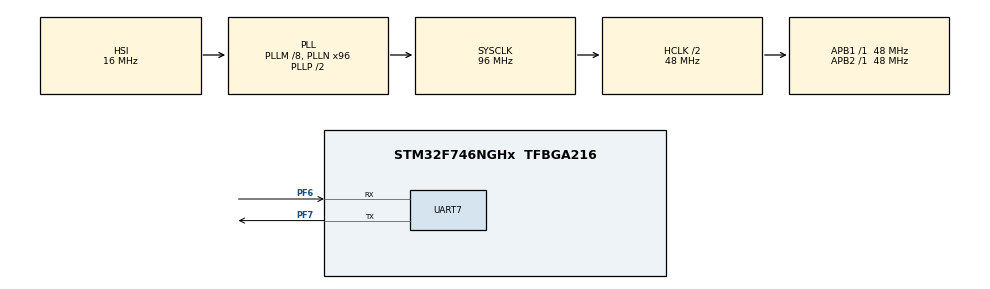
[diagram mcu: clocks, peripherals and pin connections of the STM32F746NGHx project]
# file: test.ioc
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Dma.Request0=UART7_RX
Dma.Request1=UART7_TX
Dma.UART7_RX.0.Direction=DMA_PERIPH_TO_MEMORY
Dma.UART7_RX.0.FIFOMode=DMA_FIFOMODE_DISABLE
Dma.UART7_RX.0.Instance=DMA1_Stream3
Dma.UART7_RX.0.MemDataAlignment=DMA_MDATAALIGN_BYTE
Dma.UART7_RX.0.MemInc=DMA_MINC_ENABLE
Dma.UART7_RX.0.Mode=DMA_NORMAL
Dma.UART7_RX.0.PeriphDataAlignment=DMA_PDATAALIGN_BYTE
Dma.UART7_RX.0.PeriphInc=DMA_PINC_DISABLE
Dma.UART7_RX.0.Priority=DMA_PRIORITY_LOW
Dma.UART7_TX.1.Direction=DMA_MEMORY_TO_PERIPH
Dma.UART7_TX.1.FIFOMode=DMA_FIFOMODE_DISABLE
Dma.UART7_TX.1.Instance=DMA1_Stream1
Dma.UART7_TX.1.MemDataAlignment=DMA_MDATAALIGN_BYTE
Dma.UART7_TX.1.MemInc=DMA_MINC_ENABLE
Dma.UART7_TX.1.Mode=DMA_NORMAL
Dma.UART7_TX.1.PeriphDataAlignment=DMA_PDATAALIGN_BYTE
Dma.UART7_TX.1.PeriphInc=DMA_PINC_DISABLE
Dma.UART7_TX.1.Priority=DMA_PRIORITY_LOW
Mcu.Family=STM32F7
Mcu.Name=STM32F746NGHx
Mcu.Package=TFBGA216
NVIC.DMA1_Stream1_IRQn=true\:0\:0\:false\:false\:true\:false
NVIC.DMA1_Stream3_IRQn=true\:0\:0\:false\:false\:true\:false
NVIC.PriorityGroup=NVIC_PRIORITYGROUP_4
NVIC.UART7_IRQn=true\:0\:0\:false\:false\:true\:true
PF6.Mode=Asynchronous
PF6.Signal=UART7_RX
PF7.Mode=Asynchronous
PF7.Signal=UART7_TX
ProjectManager.HeapSize=0x200
ProjectManager.StackSize=0x400
ProjectManager.TargetToolchain=MDK-ARM V5
RCC.AHBCLKDivider=RCC_SYSCLK_DIV2
RCC.AHBFreq_Value=48000000
RCC.APB1Freq_Value=48000000
RCC.APB1TimFreq_Value=48000000
RCC.APB2Freq_Value=48000000
RCC.APB2TimFreq_Value=48000000
RCC.CortexFreq_Value=48000000
RCC.HCLKFreq_Value=48000000
RCC.HSE_VALUE=25000000
RCC.HSI_VALUE=16000000
RCC.LSE_VALUE=32768
RCC.PLLM=8
RCC.PLLN=96
RCC.SYSCLKFreq_VALUE=96000000
RCC.SYSCLKSource=RCC_SYSCLKSOURCE_PLLCLK
RCC.USBFreq_Value=96000000
RCC.VCOOutputFreq_Value=192000000
board=custom

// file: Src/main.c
/* USER CODE BEGIN Header */
/**
  ******************************************************************************
  * @file           : main.c
  * @brief          : Main program body
  ******************************************************************************
  ** This notice applies to any and all portions of this file
  * that are not between comment pairs USER CODE BEGIN and
  * USER CODE END. Other portions of this file, whether
  * inserted by the user or by software development tools
  * are owned by their respective copyright owners.
  *
  * COPYRIGHT(c) 2019 STMicroelectronics
  *
  * Redistribution and use in source and binary forms, with or without modification,
  * are permitted provided that the following conditions are met:
  *   1. Redistributions of source code must retain the above copyright notice,
  *      this list of conditions and the following disclaimer.
  *   2. Redistributions in binary form must reproduce the above copyright notice,
  *      this list of conditions and the following disclaimer in the documentation
  *      and/or other materials provided with the distribution.
  *   3. Neither the name of STMicroelectronics nor the names of its contributors
  *      may be used to endorse or promote products derived from this software
  *      without specific prior written permission.
  *
  * THIS SOFTWARE IS PROVIDED BY THE COPYRIGHT HOLDERS AND CONTRIBUTORS "AS IS"
  * AND ANY EXPRESS OR IMPLIED WARRANTIES, INCLUDING, BUT NOT LIMITED TO, THE
  * IMPLIED WARRANTIES OF MERCHANTABILITY AND FITNESS FOR A PARTICULAR PURPOSE ARE
  * DISCLAIMED. IN NO EVENT SHALL THE COPYRIGHT HOLDER OR CONTRIBUTORS BE LIABLE
  * FOR ANY DIRECT, INDIRECT, INCIDENTAL, SPECIAL, EXEMPLARY, OR CONSEQUENTIAL
  * DAMAGES (INCLUDING, BUT NOT LIMITED TO, PROCUREMENT OF SUBSTITUTE GOODS OR
  * SERVICES; LOSS OF USE, DATA, OR PROFITS; OR BUSINESS INTERRUPTION) HOWEVER
  * CAUSED AND ON ANY THEORY OF LIABILITY, WHETHER IN CONTRACT, STRICT LIABILITY,
  * OR TORT (INCLUDING NEGLIGENCE OR OTHERWISE) ARISING IN ANY WAY OUT OF THE USE
  * OF THIS SOFTWARE, EVEN IF ADVISED OF THE POSSIBILITY OF SUCH DAMAGE123.
  *
  ******************************************************************************
  */
/* USER CODE END Header */

#include "main.h"
#include "dma.h"
#include "usart.h"
#include "gpio.h"

/* USER CODE BEGIN Includes */
HAL_StatusTypeDef state;
/* USER CODE END Includes */

/* USER CODE BEGIN PTD */
 //this is just for testing git
/* USER CODE END PTD */

void SystemClock_Config(void);

/* USER CODE BEGIN 0 */
uint8_t transfer_buffer[]="hello world\r\n";
/* USER CODE END 0 */

int main(void)
{

  /* MCU Configuration--------------------------------------------------------*/

  /* Reset of all peripherals, Initializes the Flash interface and the Systick. */
  HAL_Init();

  /* Configure the system clock */
  SystemClock_Config();

  /* Initialize all configured peripherals */
  MX_GPIO_Init();
  MX_DMA_Init();
  MX_UART7_Init();

  /* Infinite loop */
  while (1)
  {

    /* USER CODE BEGIN 3 */
//		HAL_UART_Transmit_DMA(&huart7, transfer_buffer, sizeof(transfer_buffer)-1);
		printf(transfer_buffer);
		HAL_Delay(700);
  }
  /* USER CODE END 3 */
}

void SystemClock_Config(void)
{
  RCC_OscInitTypeDef RCC_OscInitStruct = {0};
  RCC_ClkInitTypeDef RCC_ClkInitStruct = {0};
  RCC_PeriphCLKInitTypeDef PeriphClkInitStruct = {0};

  /**Configure the main internal regulator output voltage
  */
  __HAL_RCC_PWR_CLK_ENABLE();
  __HAL_PWR_VOLTAGESCALING_CONFIG(PWR_REGULATOR_VOLTAGE_SCALE3);
  /**Initializes the CPU, AHB and APB busses clocks
  */
  RCC_OscInitStruct.OscillatorType = RCC_OSCILLATORTYPE_HSI;
  RCC_OscInitStruct.HSIState = RCC_HSI_ON;
  RCC_OscInitStruct.HSICalibrationValue = RCC_HSICALIBRATION_DEFAULT;
  RCC_OscInitStruct.PLL.PLLState = RCC_PLL_ON;
  RCC_OscInitStruct.PLL.PLLSource = RCC_PLLSOURCE_HSI;
  RCC_OscInitStruct.PLL.PLLM = 8;
  RCC_OscInitStruct.PLL.PLLN = 96;
  RCC_OscInitStruct.PLL.PLLP = RCC_PLLP_DIV2;
  RCC_OscInitStruct.PLL.PLLQ = 2;
  if (HAL_RCC_OscConfig(&RCC_OscInitStruct) != HAL_OK)
  {
    Error_Handler();
  }
  /**Activate the Over-Drive mode
  */
  if (HAL_PWREx_EnableOverDrive() != HAL_OK)
  {
    Error_Handler();
  }
  /**Initializes the CPU, AHB and APB busses clocks
  */
  RCC_ClkInitStruct.ClockType = RCC_CLOCKTYPE_HCLK|RCC_CLOCKTYPE_SYSCLK
                              |RCC_CLOCKTYPE_PCLK1|RCC_CLOCKTYPE_PCLK2;
  RCC_ClkInitStruct.SYSCLKSource = RCC_SYSCLKSOURCE_PLLCLK;
  RCC_ClkInitStruct.AHBCLKDivider = RCC_SYSCLK_DIV2;
  RCC_ClkInitStruct.APB1CLKDivider = RCC_HCLK_DIV1;
  RCC_ClkInitStruct.APB2CLKDivider = RCC_HCLK_DIV1;

  if (HAL_RCC_ClockConfig(&RCC_ClkInitStruct, FLASH_LATENCY_1) != HAL_OK)
  {
    Error_Handler();
  }
  PeriphClkInitStruct.PeriphClockSelection = RCC_PERIPHCLK_UART7;
  PeriphClkInitStruct.Uart7ClockSelection = RCC_UART7CLKSOURCE_PCLK1;
  if (HAL_RCCEx_PeriphCLKConfig(&PeriphClkInitStruct) != HAL_OK)
  {
    Error_Handler();
  }
}

void Error_Handler(void)
{
}

//Retarget putc function
/**
 * \brief           Printf character handler
 * \param[in]       ch: Character to send
 * \param[in]       f: File pointer
 * \return          Written character
 */
#ifdef __GNUC__
int __io_putchar(int ch) {
#else
int fputc(int ch, FILE* fil) {
#endif
	char char_1[1];

  sprintf(char_1,"%c",ch);
  state = HAL_UART_Transmit_DMA(&huart7, (uint8_t*)char_1, 10);
  if(state != HAL_OK)
  {
    while(1);
  }
    return ch;
}

/************************ (C) COPYRIGHT STMicroelectronics *****END OF FILE****/
